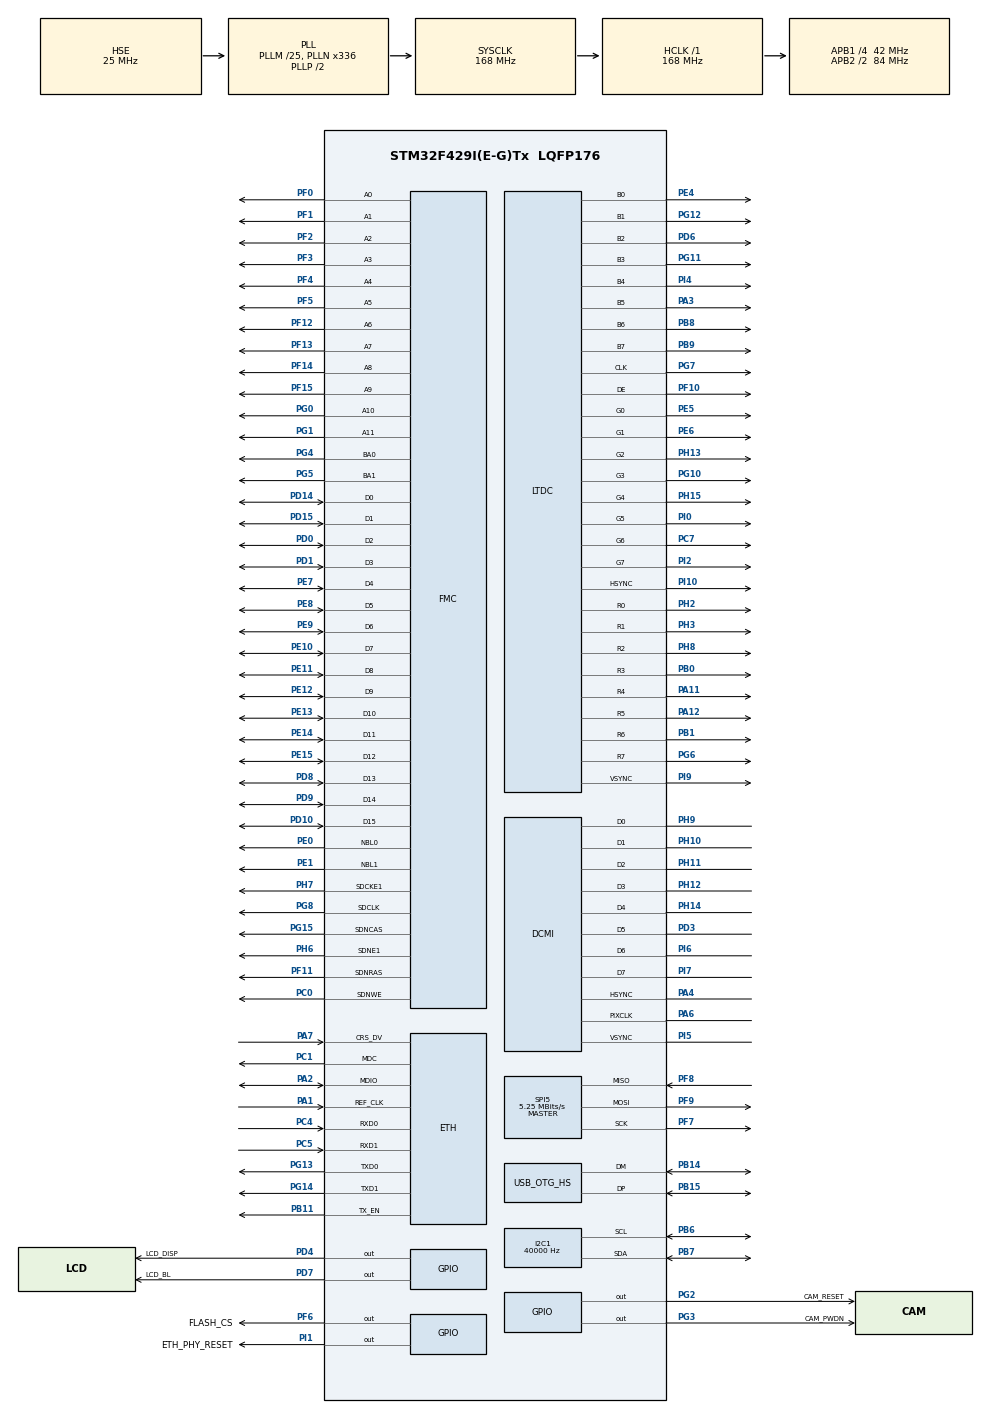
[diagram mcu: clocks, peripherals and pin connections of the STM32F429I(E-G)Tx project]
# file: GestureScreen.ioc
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DCMI.CaptureRate=DCMI_CR_ALL_FRAME
DCMI.HSPolarity=DCMI_HSPOLARITY_LOW
DCMI.PCKPolarity=DCMI_PCKPOLARITY_RISING
DCMI.VSPolarity=DCMI_VSPOLARITY_LOW
Dma.DCMI.0.Direction=DMA_PERIPH_TO_MEMORY
Dma.DCMI.0.FIFOMode=DMA_FIFOMODE_ENABLE
Dma.DCMI.0.FIFOThreshold=DMA_FIFO_THRESHOLD_FULL
Dma.DCMI.0.Instance=DMA2_Stream1
Dma.DCMI.0.MemBurst=DMA_MBURST_SINGLE
Dma.DCMI.0.MemDataAlignment=DMA_MDATAALIGN_WORD
Dma.DCMI.0.MemInc=DMA_MINC_ENABLE
Dma.DCMI.0.Mode=DMA_NORMAL
Dma.DCMI.0.PeriphBurst=DMA_PBURST_SINGLE
Dma.DCMI.0.PeriphDataAlignment=DMA_PDATAALIGN_WORD
Dma.DCMI.0.PeriphInc=DMA_PINC_DISABLE
Dma.DCMI.0.Priority=DMA_PRIORITY_VERY_HIGH
Dma.Request0=DCMI
ETH.MediaInterface=HAL_ETH_RMII_MODE
ETH.RxBuffLen=1536
FMC.CASLatency1=FMC_SDRAM_CAS_LATENCY_3
FMC.ColumnBitsNumber1=FMC_SDRAM_COLUMN_BITS_NUM_8
FMC.ExitSelfRefreshDelay1=7
FMC.LoadToActiveDelay1=2
FMC.RCDDelay1=2
FMC.RPDelay1=2
FMC.ReadBurst1=FMC_SDRAM_RBURST_DISABLE
FMC.ReadPipeDelay1=FMC_SDRAM_RPIPE_DELAY_1
FMC.RowBitsNumber1=FMC_SDRAM_ROW_BITS_NUM_12
FMC.RowCycleDelay1=7
FMC.SDBank1=FMC_SDRAM_BANK2
FMC.SDClockPeriod1=FMC_SDRAM_CLOCK_PERIOD_2
FMC.SelfRefreshTime1=4
FMC.WriteRecoveryTime1=3
FREERTOS.Tasks01=defaultTask,24,256,StartDefaultTask,Default,NULL,Dynamic,NULL,NULL
FREERTOS.configCHECK_FOR_STACK_OVERFLOW=2
FREERTOS.configTOTAL_HEAP_SIZE=24576
FREERTOS.configUSE_MALLOC_FAILED_HOOK=1
I2C1.ClockSpeed=40000
IWDG.Prescaler=IWDG_PRESCALER_64
IWDG.Reload=2047
LTDC.AccumulatedActiveH=503
LTDC.AccumulatedActiveW=846
LTDC.AccumulatedHBP=46
LTDC.AccumulatedVBP=23
LTDC.ActiveH=480
LTDC.ActiveW=800
LTDC.Alpha0_L0=0
LTDC.Alpha_L0=255
LTDC.DEPolarity=LTDC_DEPOLARITY_AL
LTDC.FBStartAdress_L0=0xD0000000
LTDC.HBP=46
LTDC.HFP=20
LTDC.HSPolarity=LTDC_HSPOLARITY_AL
LTDC.HSync=1
LTDC.HorizontalSync=0
LTDC.ImageHeight_L0=480
LTDC.ImageWidth_L0=800
LTDC.Layers=0
LTDC.PCPolarity=LTDC_PCPOLARITY_IPC
LTDC.PixelFormat_L0=LTDC_PIXEL_FORMAT_RGB565
LTDC.TotalHeigh=525
LTDC.TotalWidth=866
LTDC.VBP=23
LTDC.VFP=22
LTDC.VSPolarity=LTDC_VSPOLARITY_AL
LTDC.VSync=1
LTDC.VerticalSync=0
LTDC.WindowX0_L0=0
LTDC.WindowX1_L0=800
LTDC.WindowY0_L0=0
LTDC.WindowY1_L0=480
Mcu.Family=STM32F4
Mcu.Name=STM32F429I(E-G)Tx
Mcu.Package=LQFP176
NVIC.DCMI_IRQn=true\:5\:0\:false\:false\:true\:true\:true\:true\:true
NVIC.DMA2_Stream1_IRQn=true\:5\:0\:false\:false\:true\:true\:true\:true\:true
NVIC.ETH_IRQn=true\:5\:0\:false\:false\:true\:true\:true\:true\:true
NVIC.LTDC_ER_IRQn=true\:5\:0\:false\:false\:true\:true\:true\:true\:true
NVIC.LTDC_IRQn=true\:5\:0\:false\:false\:true\:true\:true\:true\:true
NVIC.OTG_HS_IRQn=true\:5\:0\:false\:false\:true\:true\:true\:true\:true
NVIC.PriorityGroup=NVIC_PRIORITYGROUP_4
NVIC.TIM6_DAC_IRQn=true\:15\:0\:false\:false\:true\:false\:false\:true\:true
NVIC.TimeBase=TIM6_DAC_IRQn
NVIC.TimeBaseIP=TIM6
PA1.GPIO_Speed=GPIO_SPEED_FREQ_VERY_HIGH
PA1.Mode=RMII
PA1.Signal=ETH_REF_CLK
PA11.GPIO_Speed=GPIO_SPEED_FREQ_VERY_HIGH
PA11.Mode=RGB888
PA11.Signal=LTDC_R4
PA12.GPIO_Speed=GPIO_SPEED_FREQ_VERY_HIGH
PA12.Mode=RGB888
PA12.Signal=LTDC_R5
PA13.Mode=Serial_Wire
PA13.Signal=SYS_JTMS-SWDIO
PA14.Mode=Serial_Wire
PA14.Signal=SYS_JTCK-SWCLK
PA2.GPIO_Speed=GPIO_SPEED_FREQ_VERY_HIGH
PA2.Mode=RMII
PA2.Signal=ETH_MDIO
PA3.GPIO_Speed=GPIO_SPEED_FREQ_VERY_HIGH
PA3.Mode=RGB888
PA3.Signal=LTDC_B5
PA4.GPIO_Speed=GPIO_SPEED_FREQ_VERY_HIGH
PA4.Mode=Slave_8_bits_External_Synchro
PA4.Signal=DCMI_HSYNC
PA6.GPIO_Speed=GPIO_SPEED_FREQ_VERY_HIGH
PA6.Mode=Slave_8_bits_External_Synchro
PA6.Signal=DCMI_PIXCLK
PA7.GPIO_Speed=GPIO_SPEED_FREQ_VERY_HIGH
PA7.Mode=RMII
PA7.Signal=ETH_CRS_DV
PB0.GPIO_Speed=GPIO_SPEED_FREQ_VERY_HIGH
PB0.Mode=RGB888
PB0.Signal=LTDC_R3
PB1.GPIO_Speed=GPIO_SPEED_FREQ_VERY_HIGH
PB1.Mode=RGB888
PB1.Signal=LTDC_R6
PB11.GPIO_Speed=GPIO_SPEED_FREQ_VERY_HIGH
PB11.Mode=RMII
PB11.Signal=ETH_TX_EN
PB14.Mode=Device_Only_FS
PB14.Signal=USB_OTG_HS_DM
PB15.Mode=Device_Only_FS
PB15.Signal=USB_OTG_HS_DP
PB6.Mode=I2C
PB6.Signal=I2C1_SCL
PB7.Mode=I2C
PB7.Signal=I2C1_SDA
PB8.GPIO_Speed=GPIO_SPEED_FREQ_VERY_HIGH
PB8.Mode=RGB888
PB8.Signal=LTDC_B6
PB9.GPIO_Speed=GPIO_SPEED_FREQ_VERY_HIGH
PB9.Mode=RGB888
PB9.Signal=LTDC_B7
PC0.GPIO_Speed=GPIO_SPEED_FREQ_VERY_HIGH
PC0.Signal=FMC_SDNWE
PC1.GPIO_Speed=GPIO_SPEED_FREQ_VERY_HIGH
PC1.Mode=RMII
PC1.Signal=ETH_MDC
PC4.GPIO_Speed=GPIO_SPEED_FREQ_VERY_HIGH
PC4.Mode=RMII
PC4.Signal=ETH_RXD0
PC5.GPIO_Speed=GPIO_SPEED_FREQ_VERY_HIGH
PC5.Mode=RMII
PC5.Signal=ETH_RXD1
PC7.GPIO_Speed=GPIO_SPEED_FREQ_VERY_HIGH
PC7.Mode=RGB888
PC7.Signal=LTDC_G6
PD0.GPIO_Speed=GPIO_SPEED_FREQ_VERY_HIGH
PD0.Signal=FMC_D2_DA2
PD1.GPIO_Speed=GPIO_SPEED_FREQ_VERY_HIGH
PD1.Signal=FMC_D3_DA3
PD10.GPIO_Speed=GPIO_SPEED_FREQ_VERY_HIGH
PD10.Signal=FMC_D15_DA15
PD14.GPIO_Speed=GPIO_SPEED_FREQ_VERY_HIGH
PD14.Signal=FMC_D0_DA0
PD15.GPIO_Speed=GPIO_SPEED_FREQ_VERY_HIGH
PD15.Signal=FMC_D1_DA1
PD3.GPIO_Speed=GPIO_SPEED_FREQ_VERY_HIGH
PD3.Mode=Slave_8_bits_External_Synchro
PD3.Signal=DCMI_D5
PD4.GPIO_Label=LCD_DISP
PD4.GPIO_PuPd=GPIO_NOPULL
PD4.GPIO_Speed=GPIO_SPEED_FREQ_LOW
PD4.PinState=GPIO_PIN_RESET
PD4.Signal=GPIO_Output
PD6.GPIO_Speed=GPIO_SPEED_FREQ_VERY_HIGH
PD6.Mode=RGB888
PD6.Signal=LTDC_B2
PD7.GPIO_Label=LCD_BL
PD7.GPIO_PuPd=GPIO_NOPULL
PD7.GPIO_Speed=GPIO_SPEED_FREQ_LOW
PD7.PinState=GPIO_PIN_RESET
PD7.Signal=GPIO_Output
PD8.GPIO_Speed=GPIO_SPEED_FREQ_VERY_HIGH
PD8.Signal=FMC_D13_DA13
PD9.GPIO_Speed=GPIO_SPEED_FREQ_VERY_HIGH
PD9.Signal=FMC_D14_DA14
PE0.GPIO_Speed=GPIO_SPEED_FREQ_VERY_HIGH
PE0.Signal=FMC_NBL0
PE1.GPIO_Speed=GPIO_SPEED_FREQ_VERY_HIGH
PE1.Signal=FMC_NBL1
PE10.GPIO_Speed=GPIO_SPEED_FREQ_VERY_HIGH
PE10.Signal=FMC_D7_DA7
PE11.GPIO_Speed=GPIO_SPEED_FREQ_VERY_HIGH
PE11.Signal=FMC_D8_DA8
PE12.GPIO_Speed=GPIO_SPEED_FREQ_VERY_HIGH
PE12.Signal=FMC_D9_DA9
PE13.GPIO_Speed=GPIO_SPEED_FREQ_VERY_HIGH
PE13.Signal=FMC_D10_DA10
PE14.GPIO_Speed=GPIO_SPEED_FREQ_VERY_HIGH
PE14.Signal=FMC_D11_DA11
PE15.GPIO_Speed=GPIO_SPEED_FREQ_VERY_HIGH
PE15.Signal=FMC_D12_DA12
PE4.GPIO_Speed=GPIO_SPEED_FREQ_VERY_HIGH
PE4.Mode=RGB888
PE4.Signal=LTDC_B0
PE5.GPIO_Speed=GPIO_SPEED_FREQ_VERY_HIGH
PE5.Mode=RGB888
PE5.Signal=LTDC_G0
PE6.GPIO_Speed=GPIO_SPEED_FREQ_VERY_HIGH
PE6.Mode=RGB888
PE6.Signal=LTDC_G1
PE7.GPIO_Speed=GPIO_SPEED_FREQ_VERY_HIGH
PE7.Signal=FMC_D4_DA4
PE8.GPIO_Speed=GPIO_SPEED_FREQ_VERY_HIGH
PE8.Signal=FMC_D5_DA5
PE9.GPIO_Speed=GPIO_SPEED_FREQ_VERY_HIGH
PE9.Signal=FMC_D6_DA6
PF0.GPIO_Speed=GPIO_SPEED_FREQ_VERY_HIGH
PF0.Signal=FMC_A0
PF1.GPIO_Speed=GPIO_SPEED_FREQ_VERY_HIGH
PF1.Signal=FMC_A1
PF10.GPIO_Speed=GPIO_SPEED_FREQ_VERY_HIGH
PF10.Mode=RGB888
PF10.Signal=LTDC_DE
PF11.GPIO_Speed=GPIO_SPEED_FREQ_VERY_HIGH
PF11.Signal=FMC_SDNRAS
PF12.GPIO_Speed=GPIO_SPEED_FREQ_VERY_HIGH
PF12.Signal=FMC_A6
PF13.GPIO_Speed=GPIO_SPEED_FREQ_VERY_HIGH
PF13.Signal=FMC_A7
PF14.GPIO_Speed=GPIO_SPEED_FREQ_VERY_HIGH
PF14.Signal=FMC_A8
PF15.GPIO_Speed=GPIO_SPEED_FREQ_VERY_HIGH
PF15.Signal=FMC_A9
PF2.GPIO_Speed=GPIO_SPEED_FREQ_VERY_HIGH
PF2.Signal=FMC_A2
PF3.GPIO_Speed=GPIO_SPEED_FREQ_VERY_HIGH
PF3.Signal=FMC_A3
PF4.GPIO_Speed=GPIO_SPEED_FREQ_VERY_HIGH
PF4.Signal=FMC_A4
PF5.GPIO_Speed=GPIO_SPEED_FREQ_VERY_HIGH
PF5.Signal=FMC_A5
PF6.GPIO_Label=FLASH_CS
PF6.GPIO_PuPd=GPIO_NOPULL
PF6.GPIO_Speed=GPIO_SPEED_FREQ_LOW
PF6.PinState=GPIO_PIN_SET
PF6.Signal=GPIO_Output
PF7.GPIO_Speed=GPIO_SPEED_FREQ_VERY_HIGH
PF7.Mode=Full_Duplex_Master
PF7.Signal=SPI5_SCK
PF8.GPIO_Speed=GPIO_SPEED_FREQ_VERY_HIGH
PF8.Mode=Full_Duplex_Master
PF8.Signal=SPI5_MISO
PF9.GPIO_Speed=GPIO_SPEED_FREQ_VERY_HIGH
PF9.Mode=Full_Duplex_Master
PF9.Signal=SPI5_MOSI
PG0.GPIO_Speed=GPIO_SPEED_FREQ_VERY_HIGH
PG0.Signal=FMC_A10
PG1.GPIO_Speed=GPIO_SPEED_FREQ_VERY_HIGH
PG1.Signal=FMC_A11
PG10.GPIO_Speed=GPIO_SPEED_FREQ_VERY_HIGH
PG10.Mode=RGB888
PG10.Signal=LTDC_G3
PG11.GPIO_Speed=GPIO_SPEED_FREQ_VERY_HIGH
PG11.Mode=RGB888
PG11.Signal=LTDC_B3
PG12.GPIO_Speed=GPIO_SPEED_FREQ_VERY_HIGH
PG12.Mode=RGB888
PG12.Signal=LTDC_B1
PG13.GPIO_Speed=GPIO_SPEED_FREQ_VERY_HIGH
PG13.Mode=RMII
PG13.Signal=ETH_TXD0
PG14.GPIO_Speed=GPIO_SPEED_FREQ_VERY_HIGH
PG14.Mode=RMII
PG14.Signal=ETH_TXD1
PG15.GPIO_Speed=GPIO_SPEED_FREQ_VERY_HIGH
PG15.Signal=FMC_SDNCAS
PG2.GPIO_Label=CAM_RESET
PG2.GPIO_PuPd=GPIO_NOPULL
PG2.GPIO_Speed=GPIO_SPEED_FREQ_LOW
PG2.PinState=GPIO_PIN_RESET
PG2.Signal=GPIO_Output
PG3.GPIO_Label=CAM_PWDN
PG3.GPIO_PuPd=GPIO_NOPULL
PG3.GPIO_Speed=GPIO_SPEED_FREQ_LOW
PG3.PinState=GPIO_PIN_SET
PG3.Signal=GPIO_Output
PG4.GPIO_Speed=GPIO_SPEED_FREQ_VERY_HIGH
PG4.Signal=FMC_A14_BA0
PG5.GPIO_Speed=GPIO_SPEED_FREQ_VERY_HIGH
PG5.Signal=FMC_A15_BA1
PG6.GPIO_Speed=GPIO_SPEED_FREQ_VERY_HIGH
PG6.Mode=RGB888
PG6.Signal=LTDC_R7
PG7.GPIO_Speed=GPIO_SPEED_FREQ_VERY_HIGH
PG7.Mode=RGB888
PG7.Signal=LTDC_CLK
PG8.GPIO_Speed=GPIO_SPEED_FREQ_VERY_HIGH
PG8.Signal=FMC_SDCLK
PH0/OSC_IN.Mode=HSE-External-Oscillator
PH0/OSC_IN.Signal=RCC_OSC_IN
PH1/OSC_OUT.Mode=HSE-External-Oscillator
PH1/OSC_OUT.Signal=RCC_OSC_OUT
PH10.GPIO_Speed=GPIO_SPEED_FREQ_VERY_HIGH
PH10.Mode=Slave_8_bits_External_Synchro
PH10.Signal=DCMI_D1
PH11.GPIO_Speed=GPIO_SPEED_FREQ_VERY_HIGH
PH11.Mode=Slave_8_bits_External_Synchro
PH11.Signal=DCMI_D2
PH12.GPIO_Speed=GPIO_SPEED_FREQ_VERY_HIGH
PH12.Mode=Slave_8_bits_External_Synchro
PH12.Signal=DCMI_D3
PH13.GPIO_Speed=GPIO_SPEED_FREQ_VERY_HIGH
PH13.Mode=RGB888
PH13.Signal=LTDC_G2
PH14.GPIO_Speed=GPIO_SPEED_FREQ_VERY_HIGH
PH14.Mode=Slave_8_bits_External_Synchro
PH14.Signal=DCMI_D4
PH15.GPIO_Speed=GPIO_SPEED_FREQ_VERY_HIGH
PH15.Mode=RGB888
PH15.Signal=LTDC_G4
PH2.GPIO_Speed=GPIO_SPEED_FREQ_VERY_HIGH
PH2.Mode=RGB888
PH2.Signal=LTDC_R0
PH3.GPIO_Speed=GPIO_SPEED_FREQ_VERY_HIGH
PH3.Mode=RGB888
PH3.Signal=LTDC_R1
PH6.GPIO_Speed=GPIO_SPEED_FREQ_VERY_HIGH
PH6.Mode=SdramChipSelect2_1
PH6.Signal=FMC_SDNE1
PH7.GPIO_Speed=GPIO_SPEED_FREQ_VERY_HIGH
PH7.Mode=SdramChipSelect2_1
PH7.Signal=FMC_SDCKE1
PH8.GPIO_Speed=GPIO_SPEED_FREQ_VERY_HIGH
PH8.Mode=RGB888
PH8.Signal=LTDC_R2
PH9.GPIO_Speed=GPIO_SPEED_FREQ_VERY_HIGH
PH9.Mode=Slave_8_bits_External_Synchro
PH9.Signal=DCMI_D0
PI0.GPIO_Speed=GPIO_SPEED_FREQ_VERY_HIGH
PI0.Mode=RGB888
PI0.Signal=LTDC_G5
PI1.GPIO_Label=ETH_PHY_RESET
PI1.GPIO_PuPd=GPIO_NOPULL
PI1.GPIO_Speed=GPIO_SPEED_FREQ_LOW
PI1.PinState=GPIO_PIN_RESET
PI1.Signal=GPIO_Output
PI10.GPIO_Speed=GPIO_SPEED_FREQ_VERY_HIGH
PI10.Mode=RGB888
PI10.Signal=LTDC_HSYNC
PI2.GPIO_Speed=GPIO_SPEED_FREQ_VERY_HIGH
PI2.Mode=RGB888
PI2.Signal=LTDC_G7
PI4.GPIO_Speed=GPIO_SPEED_FREQ_VERY_HIGH
PI4.Mode=RGB888
PI4.Signal=LTDC_B4
PI5.GPIO_Speed=GPIO_SPEED_FREQ_VERY_HIGH
PI5.Mode=Slave_8_bits_External_Synchro
PI5.Signal=DCMI_VSYNC
PI6.GPIO_Speed=GPIO_SPEED_FREQ_VERY_HIGH
PI6.Mode=Slave_8_bits_External_Synchro
PI6.Signal=DCMI_D6
PI7.GPIO_Speed=GPIO_SPEED_FREQ_VERY_HIGH
PI7.Mode=Slave_8_bits_External_Synchro
PI7.Signal=DCMI_D7
PI9.GPIO_Speed=GPIO_SPEED_FREQ_VERY_HIGH
PI9.Mode=RGB888
PI9.Signal=LTDC_VSYNC
ProjectManager.HeapSize=0x200
ProjectManager.StackSize=0x800
ProjectManager.TargetToolchain=MDK-ARM V5.32
RCC.AHBFreq_Value=168000000
RCC.APB1CLKDivider=RCC_HCLK_DIV4
RCC.APB1Freq_Value=42000000
RCC.APB1TimFreq_Value=84000000
RCC.APB2CLKDivider=RCC_HCLK_DIV2
RCC.APB2Freq_Value=84000000
RCC.APB2TimFreq_Value=168000000
RCC.CortexFreq_Value=168000000
RCC.HCLKFreq_Value=168000000
RCC.HSE_VALUE=25000000
RCC.HSI_VALUE=16000000
RCC.LSE_VALUE=32768
RCC.PLLM=25
RCC.PLLN=336
RCC.PLLP=RCC_PLLP_DIV2
RCC.PLLQ=7
RCC.PLLSAIDivR=RCC_PLLSAIDIVR_4
RCC.PLLSAIN=384
RCC.PLLSAIR=4
RCC.SYSCLKFreq_VALUE=168000000
RCC.SYSCLKSource=RCC_SYSCLKSOURCE_PLLCLK
RCC.VCOOutputFreq_Value=336000000
SH.FMC_A0.0=FMC_A0,12b-sda1
SH.FMC_A1.0=FMC_A1,12b-sda1
SH.FMC_A10.0=FMC_A10,12b-sda1
SH.FMC_A11.0=FMC_A11,12b-sda1
SH.FMC_A14_BA0.0=FMC_BA0,FourSdramBanks1
SH.FMC_A15_BA1.0=FMC_BA1,FourSdramBanks1
SH.FMC_A2.0=FMC_A2,12b-sda1
SH.FMC_A3.0=FMC_A3,12b-sda1
SH.FMC_A4.0=FMC_A4,12b-sda1
SH.FMC_A5.0=FMC_A5,12b-sda1
SH.FMC_A6.0=FMC_A6,12b-sda1
SH.FMC_A7.0=FMC_A7,12b-sda1
SH.FMC_A8.0=FMC_A8,12b-sda1
SH.FMC_A9.0=FMC_A9,12b-sda1
SH.FMC_D0_DA0.0=FMC_D0,sd-16b-d1
SH.FMC_D10_DA10.0=FMC_D10,sd-16b-d1
SH.FMC_D11_DA11.0=FMC_D11,sd-16b-d1
SH.FMC_D12_DA12.0=FMC_D12,sd-16b-d1
SH.FMC_D13_DA13.0=FMC_D13,sd-16b-d1
SH.FMC_D14_DA14.0=FMC_D14,sd-16b-d1
SH.FMC_D15_DA15.0=FMC_D15,sd-16b-d1
SH.FMC_D1_DA1.0=FMC_D1,sd-16b-d1
SH.FMC_D2_DA2.0=FMC_D2,sd-16b-d1
SH.FMC_D3_DA3.0=FMC_D3,sd-16b-d1
SH.FMC_D4_DA4.0=FMC_D4,sd-16b-d1
SH.FMC_D5_DA5.0=FMC_D5,sd-16b-d1
SH.FMC_D6_DA6.0=FMC_D6,sd-16b-d1
SH.FMC_D7_DA7.0=FMC_D7,sd-16b-d1
SH.FMC_D8_DA8.0=FMC_D8,sd-16b-d1
SH.FMC_D9_DA9.0=FMC_D9,sd-16b-d1
SH.FMC_NBL0.0=FMC_NBL0,Sd2ByteEnable1
SH.FMC_NBL1.0=FMC_NBL1,Sd2ByteEnable1
SH.FMC_SDCLK.0=FMC_SDCLK,12b-sda1
SH.FMC_SDNCAS.0=FMC_SDNCAS,12b-sda1
SH.FMC_SDNRAS.0=FMC_SDNRAS,12b-sda1
SH.FMC_SDNWE.0=FMC_SDNWE,12b-sda1
SPI5.BaudRatePrescaler=SPI_BAUDRATEPRESCALER_16
SPI5.CalculateBaudRate=5.25 MBits/s
SPI5.Direction=SPI_DIRECTION_2LINES
SPI5.Mode=SPI_MODE_MASTER
SPI5.VirtualType=VM_MASTER
USB_DEVICE.CLASS_NAME_HS=CDC
USB_DEVICE.PRODUCT_STRING_CDC_HS=GestureScreen USB Capture
USB_DEVICE.VirtualMode=Cdc
USB_DEVICE.VirtualMode-CDC_HS=Cdc
USB_DEVICE.VirtualModeHS=Cdc_HS
USB_OTG_HS.DeviceSpeed=PCD_SPEED_FULL
USB_OTG_HS.VirtualMode=Device_Only_FS
USB_OTG_HS.VirtualMode-Device_Only_FS=Device_Only_FS
USB_OTG_HS.dma_enable=DISABLE
USB_OTG_HS.phy_itface=USB_OTG_EMBEDDED_PHY
USB_OTG_HS.vbus_sensing_enable=DISABLE
VP_FREERTOS_VS_CMSIS_V2.Mode=CMSIS_V2
VP_IWDG_VS_IWDG.Mode=IWDG_Activate
VP_SYS_VS_tim6.Mode=TIM6
VP_USB_DEVICE_VS_USB_DEVICE_CDC_HS.Mode=CDC_HS
board=custom

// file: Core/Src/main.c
/* USER CODE BEGIN Header */
/**
  ******************************************************************************
  * @file           : main.c
  * @brief          : Main program body
  ******************************************************************************
  * @attention
  *
  * Copyright (c) 2026 STMicroelectronics.
  * All rights reserved.
  *
  * This software is licensed under terms that can be found in the LICENSE file
  * in the root directory of this software component.
  * If no LICENSE file comes with this software, it is provided AS-IS.
  *
  ******************************************************************************
  */
/* USER CODE END Header */
#include "main.h"
#include "cmsis_os.h"
#include "dcmi.h"
#include "dma.h"
#include "eth.h"
#include "i2c.h"
#include "iwdg.h"
#include "ltdc.h"
#include "spi.h"
#include "usb_device.h"
#include "gpio.h"
#include "fmc.h"

/* USER CODE BEGIN Includes */
#include "gs_debug.h"

/* USER CODE END Includes */

void SystemClock_Config(void);
void MX_FREERTOS_Init(void);

int main(void)
{

  /* MCU Configuration--------------------------------------------------------*/

  /* Reset of all peripherals, Initializes the Flash interface and the Systick. */
  HAL_Init();

  /* Configure the system clock */
  SystemClock_Config();

  /* USER CODE BEGIN SysInit */
  /* Halt with fireDAP without IWDG resets; running firmware still watches tasks. */
  __HAL_DBGMCU_FREEZE_IWDG();
  gs_debug_boot_init();
  /* USER CODE END SysInit */

  /* Initialize all configured peripherals */
  MX_GPIO_Init();
  MX_DMA_Init();
  MX_FMC_Init();
  MX_I2C1_Init();
  MX_SPI5_Init();
  MX_DCMI_Init();
  MX_LTDC_Init();
  MX_ETH_Init();
  MX_IWDG_Init();

  /* Init scheduler */
  osKernelInitialize();  /* Call init function for freertos objects (in cmsis_os2.c) */
  MX_FREERTOS_Init();

  /* Start scheduler */
  osKernelStart();

  /* We should never get here as control is now taken by the scheduler */

  /* Infinite loop */
  while (1)
  {

  }
}

void SystemClock_Config(void)
{
  RCC_OscInitTypeDef RCC_OscInitStruct = {0};
  RCC_ClkInitTypeDef RCC_ClkInitStruct = {0};

  /** Configure the main internal regulator output voltage
  */
  __HAL_RCC_PWR_CLK_ENABLE();
  __HAL_PWR_VOLTAGESCALING_CONFIG(PWR_REGULATOR_VOLTAGE_SCALE1);

  /** Initializes the RCC Oscillators according to the specified parameters
  * in the RCC_OscInitTypeDef structure.
  */
  RCC_OscInitStruct.OscillatorType = RCC_OSCILLATORTYPE_LSI|RCC_OSCILLATORTYPE_HSE;
  RCC_OscInitStruct.HSEState = RCC_HSE_ON;
  RCC_OscInitStruct.LSIState = RCC_LSI_ON;
  RCC_OscInitStruct.PLL.PLLState = RCC_PLL_ON;
  RCC_OscInitStruct.PLL.PLLSource = RCC_PLLSOURCE_HSE;
  RCC_OscInitStruct.PLL.PLLM = 25;
  RCC_OscInitStruct.PLL.PLLN = 336;
  RCC_OscInitStruct.PLL.PLLP = RCC_PLLP_DIV2;
  RCC_OscInitStruct.PLL.PLLQ = 7;
  if (HAL_RCC_OscConfig(&RCC_OscInitStruct) != HAL_OK)
  {
    Error_Handler();
  }

  /** Initializes the CPU, AHB and APB buses clocks
  */
  RCC_ClkInitStruct.ClockType = RCC_CLOCKTYPE_HCLK|RCC_CLOCKTYPE_SYSCLK
                              |RCC_CLOCKTYPE_PCLK1|RCC_CLOCKTYPE_PCLK2;
  RCC_ClkInitStruct.SYSCLKSource = RCC_SYSCLKSOURCE_PLLCLK;
  RCC_ClkInitStruct.AHBCLKDivider = RCC_SYSCLK_DIV1;
  RCC_ClkInitStruct.APB1CLKDivider = RCC_HCLK_DIV4;
  RCC_ClkInitStruct.APB2CLKDivider = RCC_HCLK_DIV2;

  if (HAL_RCC_ClockConfig(&RCC_ClkInitStruct, FLASH_LATENCY_5) != HAL_OK)
  {
    Error_Handler();
  }
}

void HAL_TIM_PeriodElapsedCallback(TIM_HandleTypeDef *htim)
{
  if (htim->Instance == TIM6)
  {
    HAL_IncTick();
  }
}

void Error_Handler(void)
{
  /* USER CODE BEGIN Error_Handler_Debug */
  gs_debug_fault(0xe0U);
  /* 可在此补充 HAL 错误诊断。 */
  __disable_irq();
  while (1)
  {
  }
  /* USER CODE END Error_Handler_Debug */
}
#ifdef USE_FULL_ASSERT
/**
  * @brief  Reports the name of the source file and the source line number
  *         where the assert_param error has occurred.
  * @param  file: pointer to the source file name
  * @param  line: assert_param error line source number
  * @retval None
  */
void assert_failed(uint8_t *file, uint32_t line)
{
  /* USER CODE BEGIN 6 */
  /* 可在此报告参数断言失败的文件名与行号，
     例如使用 printf 输出 file 和 line。 */
  /* USER CODE END 6 */
}
#endif /* USE_FULL_ASSERT */

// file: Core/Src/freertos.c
/* USER CODE BEGIN Header */
/**
  ******************************************************************************
  * File Name          : freertos.c
  * Description        : Code for freertos applications
  ******************************************************************************
  * @attention
  *
  * Copyright (c) 2026 STMicroelectronics.
  * All rights reserved.
  *
  * This software is licensed under terms that can be found in the LICENSE file
  * in the root directory of this software component.
  * If no LICENSE file comes with this software, it is provided AS-IS.
  *
  ******************************************************************************
  */
/* USER CODE END Header */

#include "FreeRTOS.h"
#include "task.h"
#include "main.h"
#include "cmsis_os.h"

/* USER CODE BEGIN Includes */
#include "gs_app.h"
/* USER CODE END Includes */

/* USER CODE BEGIN Variables */
/* Minimum remaining bootstrap stack space, sampled after init before deletion. */
volatile uint32_t g_gs_bootstrap_stack_free_bytes;
/* USER CODE END Variables */
/* Definitions for defaultTask */
osThreadId_t defaultTaskHandle;
const osThreadAttr_t defaultTask_attributes = {
  .name = "defaultTask",
  .stack_size = 256 * 4,
  .priority = (osPriority_t) osPriorityNormal,
};

void StartDefaultTask(void *argument);

extern void MX_USB_DEVICE_Init(void);
void MX_FREERTOS_Init(void); /* (MISRA C 2004 rule 8.1) */

/* Hook prototypes */
void vApplicationStackOverflowHook(xTaskHandle xTask, signed char *pcTaskName);
void vApplicationMallocFailedHook(void);

/* USER CODE BEGIN 4 */
void vApplicationStackOverflowHook(xTaskHandle xTask, signed char *pcTaskName)
{
  (void)xTask; (void)pcTaskName;
  gs_app_fatal(0x21U);
}
/* USER CODE END 4 */

/* USER CODE BEGIN 5 */
void vApplicationMallocFailedHook(void)
{
  gs_app_fatal(0x22U);
}
/* USER CODE END 5 */

void MX_FREERTOS_Init(void) {

  /* USER CODE BEGIN RTOS_MUTEX */
  /* 在此添加互斥量。 */
  /* USER CODE END RTOS_MUTEX */

  /* USER CODE BEGIN RTOS_SEMAPHORES */
  /* 在此添加信号量。 */
  /* USER CODE END RTOS_SEMAPHORES */

  /* USER CODE BEGIN RTOS_TIMERS */
  /* 在此创建并启动软件定时器。 */
  /* USER CODE END RTOS_TIMERS */

  /* USER CODE BEGIN RTOS_QUEUES */
  /* 应用队列由 gs_app_init 创建。 */
  /* USER CODE END RTOS_QUEUES */

  /* Create the thread(s) */
  /* creation of defaultTask */
  defaultTaskHandle = osThreadNew(StartDefaultTask, NULL, &defaultTask_attributes);

  /* USER CODE BEGIN RTOS_THREADS */
  if (defaultTaskHandle == NULL) { gs_app_fatal(0x20U); }
  /* BSP initialization runs in defaultTask after the scheduler unmasks IRQs. */
  /* USER CODE END RTOS_THREADS */

  /* USER CODE BEGIN RTOS_EVENTS */
  /* 在此添加事件对象。 */
  /* USER CODE END RTOS_EVENTS */

}

/* USER CODE BEGIN Header_StartDefaultTask */
/**
  * @brief  默认任务入口；应用使用独立的六个任务。
  * @param  argument: 未使用
  * @retval 无
  */
/* USER CODE END Header_StartDefaultTask */
void StartDefaultTask(void *argument)
{
  /* init code for USB_DEVICE */
  MX_USB_DEVICE_Init();
  /* USER CODE BEGIN StartDefaultTask */
  (void)argument;
  /* HAL_Delay requires TIM6 IRQs, which pre-scheduler task creation masks. */
  gs_app_init();
  g_gs_bootstrap_stack_free_bytes = osThreadGetStackSpace(osThreadGetId());
  /* All queues and task handles are published before the bootstrap exits. */
  osThreadExit();
  /* USER CODE END StartDefaultTask */
}
